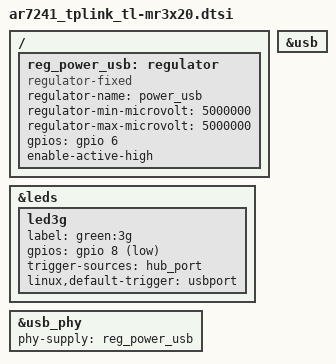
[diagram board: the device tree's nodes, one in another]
// SPDX-License-Identifier: GPL-2.0-or-later OR MIT

#include "ar7241_tplink.dtsi"

/ {
	reg_power_usb: regulator {
		compatible = "regulator-fixed";
		regulator-name = "power_usb";
		regulator-min-microvolt = <5000000>;
		regulator-max-microvolt = <5000000>;
		gpios = <&gpio 6 GPIO_ACTIVE_HIGH>;
		enable-active-high;
	};
};

&leds {
	led3g {
		label = "green:3g";
		gpios = <&gpio 8 GPIO_ACTIVE_LOW>;
		trigger-sources = <&hub_port>;
		linux,default-trigger = "usbport";
	};
};

&usb {
	status = "okay";
};

&usb_phy {
	status = "okay";

	phy-supply = <&reg_power_usb>;
};
